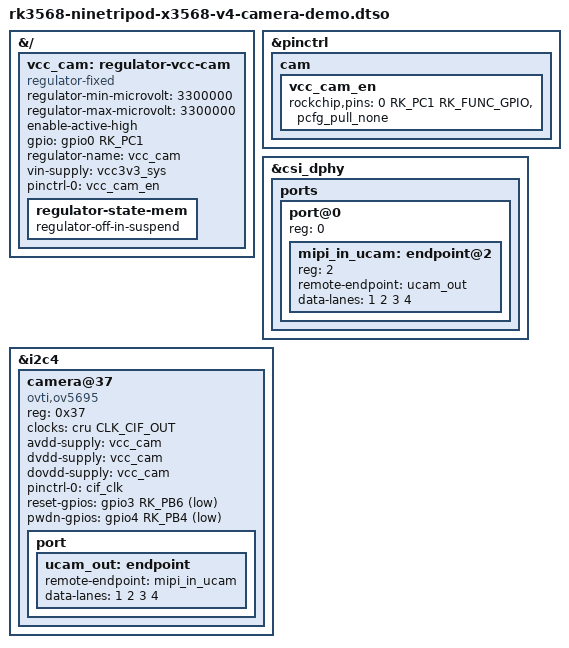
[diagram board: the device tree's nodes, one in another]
// SPDX-License-Identifier: (GPL-2.0-or-later OR MIT)

// This is a sample reference, due to lack of hardware can not be tested, at your own risk

/dts-v1/;
/plugin/;

#include <dt-bindings/clock/rk3568-cru.h>
#include <dt-bindings/gpio/gpio.h>
#include <dt-bindings/pinctrl/rockchip.h>

&{/} {
	vcc_cam: regulator-vcc-cam {
		compatible = "regulator-fixed";
		regulator-min-microvolt = <3300000>;
		regulator-max-microvolt = <3300000>;
		enable-active-high;
		gpio = <&gpio0 RK_PC1 GPIO_ACTIVE_HIGH>;
		regulator-name = "vcc_cam";
		vin-supply = <&vcc3v3_sys>;
		pinctrl-names = "default";
		pinctrl-0 = <&vcc_cam_en>;

		regulator-state-mem {
			regulator-off-in-suspend;
		};
	};
};

&pinctrl {
	cam {
		vcc_cam_en: vcc_cam_en {
			rockchip,pins =	<0 RK_PC1 RK_FUNC_GPIO &pcfg_pull_none>;
		};
	};
};

&csi_dphy {
	status = "okay";

	ports {
		#address-cells = <1>;
		#size-cells = <0>;

		port@0 {
			reg = <0>;
			#address-cells = <1>;
			#size-cells = <0>;

			mipi_in_ucam: endpoint@2 {
				reg = <2>;
				remote-endpoint = <&ucam_out>;
				data-lanes = <1 2 3 4>;
			};
		};
	};
};

&i2c4 {
	#address-cells = <1>;
	#size-cells = <0>;
	status = "okay";

	camera@37 {
		compatible = "ovti,ov5695";
		reg = <0x37>;
		clocks = <&cru CLK_CIF_OUT>;
		clock-names = "xvclk";
		avdd-supply = <&vcc_cam>;
		dvdd-supply = <&vcc_cam>;
		dovdd-supply = <&vcc_cam>;
		pinctrl-names = "default";
		pinctrl-0 = <&cif_clk>;
		reset-gpios = <&gpio3 RK_PB6 GPIO_ACTIVE_LOW>;
		pwdn-gpios = <&gpio4 RK_PB4 GPIO_ACTIVE_LOW>;

		port {
			ucam_out: endpoint {
				remote-endpoint = <&mipi_in_ucam>;
				data-lanes = <1 2 3 4>;
			};
		};
	};
};
